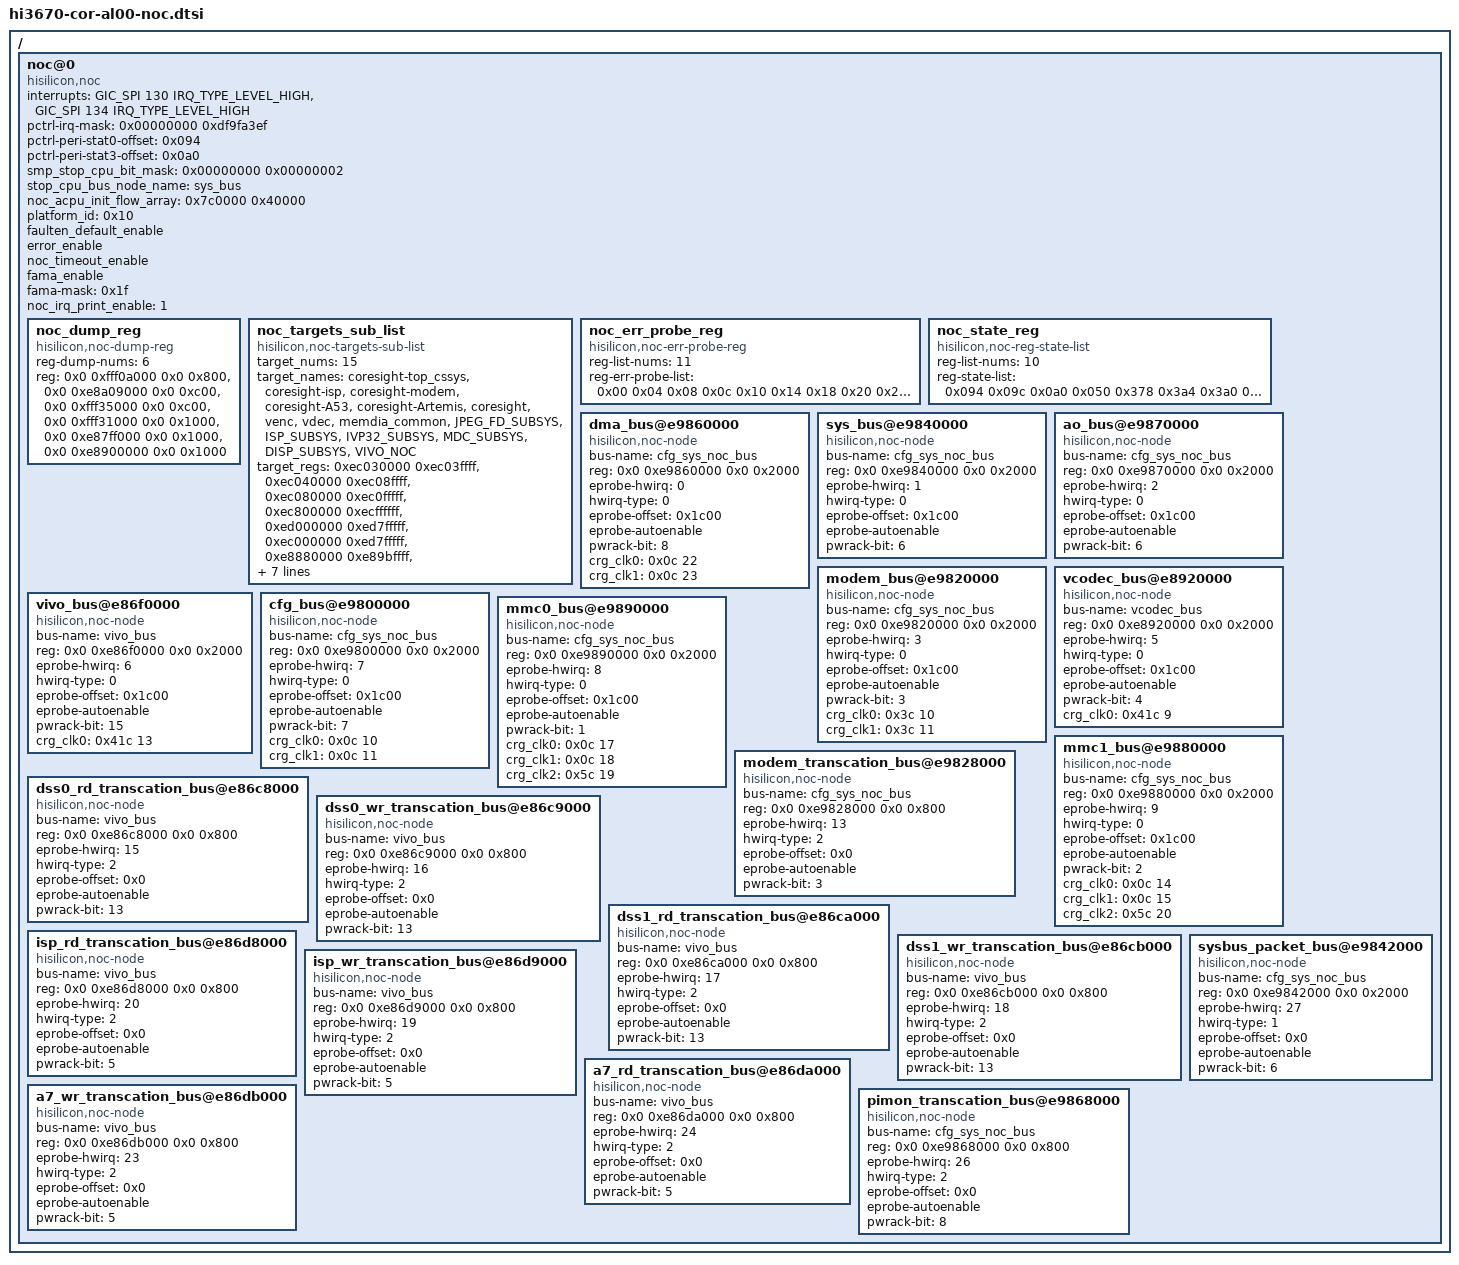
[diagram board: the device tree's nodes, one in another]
// SPDX-License-Identifier: GPL-2.0
/*
 * HiSilicon Kirin 970 (Hi3670) Network-on-Chip error monitor.
 *
 * The NoC is the AXI interconnect between the CPU clusters and the
 * peripherals.  Each bus has an error probe that latches the failing
 * initiator/target flow, address and attributes.  The node layout and
 * register offsets are taken from the vendor device tree.
 *
 * Copyright (c) 2016 Huawei Technologies Co., Ltd.
 */

#include <dt-bindings/interrupt-controller/arm-gic.h>

/ {
	noc@0 {
		#address-cells = <2>;
		#size-cells = <2>;
		ranges;
		compatible = "hisilicon,noc";
		interrupts = <GIC_SPI 130 IRQ_TYPE_LEVEL_HIGH>,
			     <GIC_SPI 134 IRQ_TYPE_LEVEL_HIGH>;
		pctrl-irq-mask = <0x00000000 0xdf9fa3ef>;
		pctrl-peri-stat0-offset = <0x094>;
		pctrl-peri-stat3-offset = <0x0a0>;
		smp_stop_cpu_bit_mask = <0x00000000 0x00000002>;  /* 0x8: 0000 0010B, Sys Bus NoC Error need stop cpu immediately.*/
		stop_cpu_bus_node_name = "sys_bus";
		noc_acpu_init_flow_array = <0x7c0000 0x40000>; /*Mask, Value*/
		platform_id = <0x10>;/* kirin970_cs(boston_cs) platform */
		faulten_default_enable;
		error_enable;
		noc_timeout_enable;
		fama_enable;
		fama-mask = <0x1f>;
		/*noc_debug;*/
		noc_irq_print_enable = <1>;

		noc_dump_reg {
			compatible = "hisilicon,noc-dump-reg";
			reg-dump-nums = <6>;
			reg = <0x0 0xfff0a000 0x0 0x800>,
			      <0x0 0xe8a09000 0x0 0xc00>,
			      <0x0 0xfff35000 0x0 0xc00>,
			      <0x0 0xfff31000 0x0 0x1000>,
			      <0x0 0xe87ff000 0x0 0x1000>,
			      <0x0 0xe8900000 0x0 0x1000>;/*media2_crg_base_addr*/
		};

		noc_targets_sub_list {
			compatible = "hisilicon,noc-targets-sub-list";
			target_nums = <15>;
			target_names = "coresight-top_cssys", "coresight-isp",
				       "coresight-modem", "coresight-A53",
				       "coresight-Artemis", "coresight", "venc", "vdec",
				       "memdia_common", "JPEG_FD_SUBSYS", "ISP_SUBSYS",
				       "IVP32_SUBSYS", "MDC_SUBSYS", "DISP_SUBSYS",
				       "VIVO_NOC";
			target_regs = <0xec030000 0xec03ffff>,
				      <0xec040000 0xec08ffff>,
				      <0xec080000 0xec0fffff>,
				      <0xec800000 0xecffffff>,
				      <0xed000000 0xed7fffff>,
				      <0xec000000 0xed7fffff>,
				      <0xe8880000 0xe89bffff>,
				      <0xe8800000 0xe883ffff>,
				      <0xe8700000 0xe879ffff>,
				      <0xe8300000 0xe83fffff>,
				      <0xe8400000 0xe85fffff>,
				      <0xe8c00000 0xe8dfffff>,
				      <0xe8700000 0xe879ffff>,
				      <0xe8600000 0xe86bffff>,
				      <0xe86c0000 0xe86fffff>;
		};

		noc_err_probe_reg {
			compatible = "hisilicon,noc-err-probe-reg";
			reg-list-nums = <11>;
			/*reg-list-offset: coreid, revisionid, faulten, errvld, errclr, errlog0, errlog1, errlog3, errlog4, errlog5, errlog7 */
			reg-err-probe-list = <0x00 0x04 0x08 0x0c 0x10 0x14 0x18 0x20 0x24 0x28 0x30>;
		};

		noc_state_reg {
			compatible = "hisilicon,noc-reg-state-list";
			reg-list-nums = <10>;
			/*reg-list-offset: pctrl_stat0, pctrl_stat2, pctrl_stat3, pctrl_ctrl19, sctrl_scperstatus6, pmctrl_int0_stat, pmctrl_int0_mask, pmctrl_power_idlereq, pmctrl_power_idleack, pmctrl_power_idle*/
			reg-state-list = <0x094 0x09c 0x0a0 0x050 0x378 0x3a4 0x3a0 0x380 0x384 0x388>;
		};

		dma_bus@e9860000 {
			compatible = "hisilicon,noc-node";
			bus-name = "cfg_sys_noc_bus";
			reg = <0x0 0xe9860000 0x0 0x2000>;
			eprobe-hwirq = <0>;
			hwirq-type = <0>;
			eprobe-offset = <0x1c00>;
			eprobe-autoenable;
			pwrack-bit = <8>;
			crg_clk0 = <0x0c 22>;
			crg_clk1 = <0x0c 23>;
		};

		sys_bus@e9840000 {
			compatible = "hisilicon,noc-node";
			bus-name = "cfg_sys_noc_bus";
			reg = <0x0 0xe9840000 0x0 0x2000>;
			eprobe-hwirq = <1>;
			hwirq-type = <0>;
			eprobe-offset = <0x1c00>;
			eprobe-autoenable;
			pwrack-bit = <6>;
		};

		ao_bus@e9870000 {
			compatible = "hisilicon,noc-node";
			bus-name = "cfg_sys_noc_bus";
			reg = <0x0 0xe9870000 0x0 0x2000>;
			eprobe-hwirq = <2>;
			hwirq-type = <0>;
			eprobe-offset = <0x1c00>;
			eprobe-autoenable;
			/*AO bus is always on and no bit controls it,
			  we use a fake control bit which keeps 1 as sysbus*/
			pwrack-bit = <6>;
		};

		modem_bus@e9820000 {
			compatible = "hisilicon,noc-node";
			bus-name = "cfg_sys_noc_bus";
			reg = <0x0 0xe9820000 0x0 0x2000>;
			eprobe-hwirq = <3>;
			hwirq-type = <0>;
			eprobe-offset = <0x1c00>;
			eprobe-autoenable;
			pwrack-bit = <3>;
			crg_clk0 = <0x3c 10>;
			crg_clk1 = <0x3c 11>;
		};

		vcodec_bus@e8920000 {
			compatible = "hisilicon,noc-node";
			bus-name = "vcodec_bus";
			reg = <0x0 0xe8920000 0x0 0x2000>;
			eprobe-hwirq = <5>;
			hwirq-type = <0>;
			eprobe-offset = <0x1c00>;
			eprobe-autoenable;
			pwrack-bit = <4>;
			crg_clk0 = <0x41c 9>;
		};

		vivo_bus@e86f0000 {
			compatible = "hisilicon,noc-node";
			bus-name = "vivo_bus";
			reg = <0x0 0xe86f0000 0x0 0x2000>;
			eprobe-hwirq = <6>;
			hwirq-type = <0>;
			eprobe-offset = <0x1c00>;
			eprobe-autoenable;
			pwrack-bit = <15>;
			crg_clk0 = <0x41c 13>;
		};

		cfg_bus@e9800000 {
			compatible = "hisilicon,noc-node";
			bus-name = "cfg_sys_noc_bus";
			reg = <0x0 0xe9800000 0x0 0x2000>;
			eprobe-hwirq = <7>;
			hwirq-type = <0>;
			eprobe-offset = <0x1c00>;
			eprobe-autoenable;
			pwrack-bit = <7>;
			crg_clk0 = <0x0c 10>;
			crg_clk1 = <0x0c 11>;
		};

		mmc0_bus@e9890000 {
			compatible = "hisilicon,noc-node";
			bus-name = "cfg_sys_noc_bus";
			reg = <0x0 0xe9890000 0x0 0x2000>;
			eprobe-hwirq = <8>;
			hwirq-type = <0>;
			eprobe-offset = <0x1c00>;
			eprobe-autoenable;
			pwrack-bit = <1>;
			crg_clk0 = <0x0c 17>;
			crg_clk1 = <0x0c 18>;
			crg_clk2 = <0x5c 19>;
		};

		mmc1_bus@e9880000 {
			compatible = "hisilicon,noc-node";
			bus-name = "cfg_sys_noc_bus";
			reg = <0x0 0xe9880000 0x0 0x2000>;
			eprobe-hwirq = <9>;
			hwirq-type = <0>;
			eprobe-offset = <0x1c00>;
			eprobe-autoenable;
			pwrack-bit = <2>;
			crg_clk0 = <0x0c 14>;
			crg_clk1 = <0x0c 15>;
			crg_clk2 = <0x5c 20>;
		};

		modem_transcation_bus@e9828000 {
			compatible = "hisilicon,noc-node";
			bus-name = "cfg_sys_noc_bus";
			reg = <0x0 0xe9828000 0x0 0x800>;
			eprobe-hwirq = <13>;
			hwirq-type = <2>;
			eprobe-offset = <0x0>;
			eprobe-autoenable;
			pwrack-bit = <3>;
		};

		dss0_rd_transcation_bus@e86c8000 {
			compatible = "hisilicon,noc-node";
			bus-name = "vivo_bus";
			reg = <0x0 0xe86c8000 0x0 0x800>;
			eprobe-hwirq = <15>;
			hwirq-type = <2>;
			eprobe-offset = <0x0>;
			eprobe-autoenable;
			pwrack-bit = <13>;
		};

		dss0_wr_transcation_bus@e86c9000 {
			compatible = "hisilicon,noc-node";
			bus-name = "vivo_bus";
			reg = <0x0 0xe86c9000 0x0 0x800>;
			eprobe-hwirq = <16>;
			hwirq-type = <2>;
			eprobe-offset = <0x0>;
			eprobe-autoenable;
			pwrack-bit = <13>;
		};

		dss1_rd_transcation_bus@e86ca000 {
			compatible = "hisilicon,noc-node";
			bus-name = "vivo_bus";
			reg = <0x0 0xe86ca000 0x0 0x800>;
			eprobe-hwirq = <17>;
			hwirq-type = <2>;
			eprobe-offset = <0x0>;
			eprobe-autoenable;
			pwrack-bit = <13>;
		};

		dss1_wr_transcation_bus@e86cb000 {
			compatible = "hisilicon,noc-node";
			bus-name = "vivo_bus";
			reg = <0x0 0xe86cb000 0x0 0x800>;
			eprobe-hwirq = <18>;
			hwirq-type = <2>;
			eprobe-offset = <0x0>;
			eprobe-autoenable;
			pwrack-bit = <13>;
		};

		isp_rd_transcation_bus@e86d8000 {
			compatible = "hisilicon,noc-node";
			bus-name = "vivo_bus";
			reg = <0x0 0xe86d8000 0x0 0x800>;
			eprobe-hwirq = <20>;
			hwirq-type = <2>;
			eprobe-offset = <0x0>;
			eprobe-autoenable;
			pwrack-bit = <5>;
		};

		isp_wr_transcation_bus@e86d9000 {
			compatible = "hisilicon,noc-node";
			bus-name = "vivo_bus";
			reg = <0x0 0xe86d9000 0x0 0x800>;
			eprobe-hwirq = <19>;
			hwirq-type = <2>;
			eprobe-offset = <0x0>;
			eprobe-autoenable;
			pwrack-bit = <5>;
		};

		a7_rd_transcation_bus@e86da000 {
			compatible = "hisilicon,noc-node";
			bus-name = "vivo_bus";
			reg = <0x0 0xe86da000 0x0 0x800>;
			eprobe-hwirq = <24>;
			hwirq-type = <2>;
			eprobe-offset = <0x0>;
			eprobe-autoenable;
			pwrack-bit = <5>;
		};

		a7_wr_transcation_bus@e86db000 {
			compatible = "hisilicon,noc-node";
			bus-name = "vivo_bus";
			reg = <0x0 0xe86db000 0x0 0x800>;
			eprobe-hwirq = <23>;
			hwirq-type = <2>;
			eprobe-offset = <0x0>;
			eprobe-autoenable;
			pwrack-bit = <5>;
		};

		/*clk of dpctrl_transcation_bus and asp_transaction_bus is asynchronous,
		 checking pwrack-bit is invalid, so need to check own clk*/
/*
		dpctrl_transcation_bus@e9898000 {
			compatible = "hisilicon,noc-node";
			bus-name = "cfg_sys_noc_bus";
			reg = <0x0 0xe9898000 0x0 0x800>;
			eprobe-hwirq = <25>;
			hwirq-type = <2>;
			eprobe-offset = <0x0>;
			eprobe-autoenable;
			pwrack-bit = <1>;
		};
*/
		pimon_transcation_bus@e9868000 {
			compatible = "hisilicon,noc-node";
			bus-name = "cfg_sys_noc_bus";
			reg = <0x0 0xe9868000 0x0 0x800>;
			eprobe-hwirq = <26>;
			hwirq-type = <2>;
			eprobe-offset = <0x0>;
			eprobe-autoenable;
			pwrack-bit = <8>;
		};

		sysbus_packet_bus@e9842000 {
			compatible = "hisilicon,noc-node";
			bus-name = "cfg_sys_noc_bus";
			reg = <0x0 0xe9842000 0x0 0x2000>;
			eprobe-hwirq = <27>;
			hwirq-type = <1>;
			eprobe-offset = <0x0>;
			eprobe-autoenable;
			pwrack-bit = <6>;
		};
/*
		asp_transaction_bus@e9838000 {
			compatible = "hisilicon,noc-node";
			bus-name = "cfg_sys_noc_bus";
			reg = <0x0 0xe9838000 0x0 0x2000>;
			eprobe-hwirq = <28>;
			hwirq-type = <2>;
			eprobe-offset = <0x0>;
			eprobe-autoenable;
			pwrack-bit = <6>;
		};
*/
	}; /* end of hisi_noc */
};
